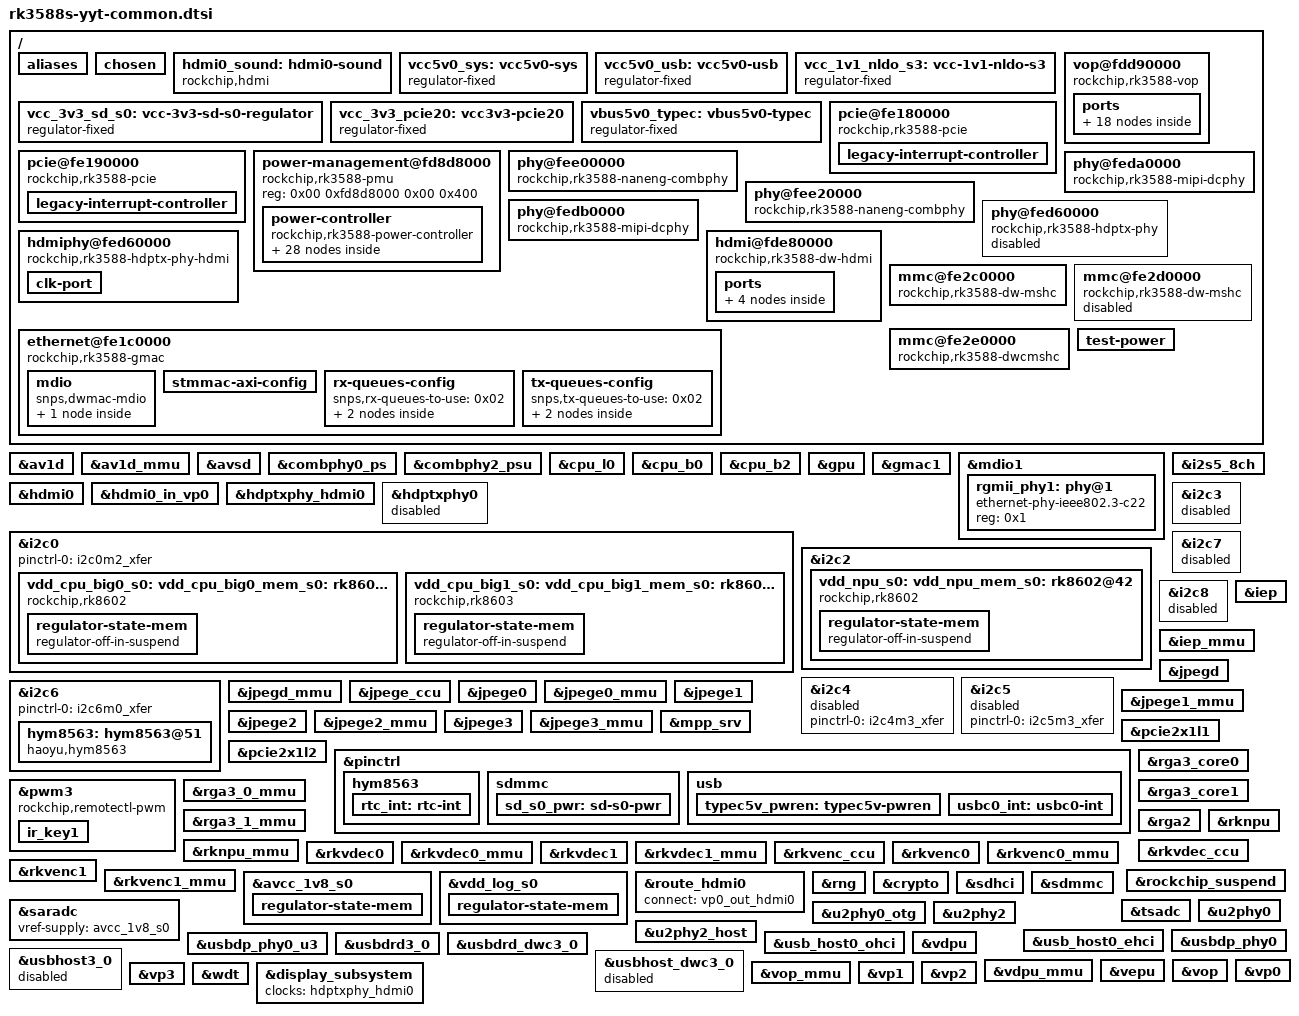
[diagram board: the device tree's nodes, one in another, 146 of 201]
// SPDX-License-Identifier: (GPL-2.0+ OR MIT)
/*
 *
 * Copyright (c) 2021 Rockchip Electronics Co., Ltd.
 */

#include <dt-bindings/gpio/gpio.h>
#include <dt-bindings/pwm/pwm.h>
#include <dt-bindings/pinctrl/rockchip.h>
#include <dt-bindings/input/rk-input.h>
#include <dt-bindings/display/drm_mipi_dsi.h>
#include <dt-bindings/display/rockchip_vop.h>
#include <dt-bindings/sensor-dev.h>
#include <dt-bindings/usb/pd.h>
#include "rk3588s.dtsi"
#include "rk3588-rk806-single.dtsi"
#include "rk3588-linux.dtsi"

/ {
	aliases {
		mmc0 = "/mmc@fe2e0000";
		mmc1 = "/mmc@fe2c0000";
		mmc2 = "/mmc@fe2d0000";
		ethernet1 = "/ethernet@fe1c0000";
	};

	chosen: chosen {
		bootargs = "earlycon=uart8250,mmio32,0xfeb50000 console=ttyFIQ0 coherent_pool=1m irqchip.gicv3_pseudo_nmi=0";
	};

	hdmi0_sound: hdmi0-sound {
		status = "disabled";
		compatible = "rockchip,hdmi";
		rockchip,mclk-fs = <128>;
		rockchip,card-name = "rockchip-hdmi0";
		rockchip,cpu = <&i2s5_8ch>;
		rockchip,codec = <&hdmi0>;
	};

	vcc5v0_sys: vcc5v0-sys {
		compatible = "regulator-fixed";
		regulator-name = "vcc5v0_sys";
		regulator-always-on;
		regulator-boot-on;
		regulator-min-microvolt = <5000000>;
		regulator-max-microvolt = <5000000>;
	};

	vcc5v0_usb: vcc5v0-usb {
		compatible = "regulator-fixed";
		regulator-name = "vcc5v0_usb";
		regulator-always-on;
		regulator-boot-on;
		regulator-min-microvolt = <5000000>;
		regulator-max-microvolt = <5000000>;
		vin-supply = <&vcc5v0_sys>;
	};

	vcc_1v1_nldo_s3: vcc-1v1-nldo-s3 {
		compatible = "regulator-fixed";
		regulator-name = "vcc_1v1_nldo_s3";
		regulator-always-on;
		regulator-boot-on;
		regulator-min-microvolt = <1100000>;
		regulator-max-microvolt = <1100000>;
		vin-supply = <&vcc5v0_sys>;
	};

	vcc_3v3_sd_s0: vcc-3v3-sd-s0-regulator {
		compatible = "regulator-fixed";
		enable-active-high;
		gpio = <&gpio4 RK_PB4 GPIO_ACTIVE_HIGH>;
		pinctrl-names = "default";
		pinctrl-0 = <&sd_s0_pwr>;
		regulator-always-on;
		regulator-boot-on;
		regulator-max-microvolt = <3000000>;
		regulator-min-microvolt = <3000000>;
		regulator-name = "vcc_3v3_sd_s0";
		vin-supply = <&vcc_3v3_s3>;
	};

	vcc_3v3_pcie20: vcc3v3-pcie20 {
		compatible = "regulator-fixed";
		regulator-name = "vcc_3v3_pcie20";
		regulator-always-on;
		regulator-boot-on;
		regulator-min-microvolt = <3300000>;
		regulator-max-microvolt = <3300000>;
		vin-supply = <&vcc_3v3_s3>;
	};

	vbus5v0_typec: vbus5v0-typec {
		compatible = "regulator-fixed";
		enable-active-high;
		gpio = <&gpio1 RK_PD2 GPIO_ACTIVE_HIGH>;
		pinctrl-names = "default";
		pinctrl-0 = <&typec5v_pwren>;
		regulator-name = "vbus5v0_typec";
		regulator-min-microvolt = <5000000>;
		regulator-max-microvolt = <5000000>;
		vin-supply = <&vcc5v0_usb>;
	};

	pcie@fe180000 {
		compatible = "rockchip,rk3588-pcie\0snps,dw-pcie";
		#address-cells = <0x03>;
		#size-cells = <0x02>;
		bus-range = <0x30 0x3f>;
		clocks = <0x02 0x151 0x02 0x156 0x02 0x14c 0x02 0x15c 0x02 0x161 0x02 0x2c5>;
		clock-names = "aclk_mst\0aclk_slv\0aclk_dbi\0pclk\0aux\0pipe";
		device_type = "pci";
		interrupts = <0x00 0xf8 0x04 0x00 0xf7 0x04 0x00 0xf6 0x04 0x00 0xf5 0x04 0x00 0xf4 0x04>;
		interrupt-names = "sys\0pmc\0msg\0legacy\0err";
		#interrupt-cells = <0x01>;
		interrupt-map-mask = <0x00 0x00 0x00 0x07>;
		interrupt-map = <0x00 0x00 0x00 0x01 0xf1 0x00 0x00 0x00 0x00 0x02 0xf1 0x01 0x00 0x00 0x00 0x03 0xf1 0x02 0x00 0x00 0x00 0x04 0xf1 0x03>;
		linux,pci-domain = <0x03>;
		num-ib-windows = <0x08>;
		num-ob-windows = <0x08>;
		num-viewport = <0x04>;
		max-link-speed = <0x02>;
		msi-map = <0x3000 0xf2 0x3000 0x1000>;
		num-lanes = <0x01>;
		phys = <0x62 0x02>;
		phy-names = "pcie-phy";
		ranges = <0x800 0x00 0xf3000000 0x00 0xf3000000 0x00 0x100000 0x81000000 0x00 0xf3100000 0x00 0xf3100000 0x00 0x100000 0x82000000 0x00 0xf3200000 0x00 0xf3200000 0x00 0xe00000 0xc3000000 0x09 0xc0000000 0x09 0xc0000000 0x00 0x40000000>;
		reg = <0x00 0xfe180000 0x00 0x10000 0x0a 0x40c00000 0x00 0x400000>;
		reg-names = "pcie-apb\0pcie-dbi";
		resets = <0x02 0x210 0x02 0x21f>;
		reset-names = "pcie\0periph";
		rockchip,pipe-grf = <0x68>;
		status = "okay";
		reset-gpios = <0xdb 0x08 0x00>;
		pedet-gpios = <0xdb 0x06 0x00>;
		vpcie3v3-supply = <0xf3>;
		rockchip,skip-scan-in-resume;

		legacy-interrupt-controller {
			interrupt-controller;
			#address-cells = <0x00>;
			#interrupt-cells = <0x01>;
			interrupt-parent = <0x01>;
			interrupts = <0x00 0xf5 0x01>;
			phandle = <0xf1>;
		};
	};

	pcie@fe190000 {
		compatible = "rockchip,rk3588-pcie\0snps,dw-pcie";
		#address-cells = <0x03>;
		#size-cells = <0x02>;
		bus-range = <0x40 0x4f>;
		clocks = <0x02 0x152 0x02 0x157 0x02 0x14d 0x02 0x15d 0x02 0x162 0x02 0x182>;
		clock-names = "aclk_mst\0aclk_slv\0aclk_dbi\0pclk\0aux\0pipe";
		device_type = "pci";
		interrupts = <0x00 0xfd 0x04 0x00 0xfc 0x04 0x00 0xfb 0x04 0x00 0xfa 0x04 0x00 0xf9 0x04>;
		interrupt-names = "sys\0pmc\0msg\0legacy\0err";
		#interrupt-cells = <0x01>;
		interrupt-map-mask = <0x00 0x00 0x00 0x07>;
		interrupt-map = <0x00 0x00 0x00 0x01 0xf4 0x00 0x00 0x00 0x00 0x02 0xf4 0x01 0x00 0x00 0x00 0x03 0xf4 0x02 0x00 0x00 0x00 0x04 0xf4 0x03>;
		linux,pci-domain = <0x04>;
		num-ib-windows = <0x08>;
		num-ob-windows = <0x08>;
		num-viewport = <0x04>;
		max-link-speed = <0x02>;
		msi-map = <0x4000 0xf2 0x4000 0x1000>;
		num-lanes = <0x01>;
		phys = <0xf5 0x02>;
		phy-names = "pcie-phy";
		ranges = <0x800 0x00 0xf4000000 0x00 0xf4000000 0x00 0x100000 0x81000000 0x00 0xf4100000 0x00 0xf4100000 0x00 0x100000 0x82000000 0x00 0xf4200000 0x00 0xf4200000 0x00 0xe00000 0xc3000000 0x0a 0x00 0x0a 0x00 0x00 0x40000000>;
		reg = <0x00 0xfe190000 0x00 0x10000 0x0a 0x41000000 0x00 0x400000>;
		reg-names = "pcie-apb\0pcie-dbi";
		resets = <0x02 0x211 0x02 0x220>;
		reset-names = "pcie\0periph";
		rockchip,pipe-grf = <0x68>;
		status = "okay";
		reset-gpios = <0xea 0x07 0x00>;
		vpcie3v3-supply = <0xf3>;
		rockchip,skip-scan-in-resume;

		legacy-interrupt-controller {
			interrupt-controller;
			#address-cells = <0x00>;
			#interrupt-cells = <0x01>;
			interrupt-parent = <0x01>;
			interrupts = <0x00 0xfa 0x01>;
			phandle = <0xf4>;
		};
	};

	vop@fdd90000 {
		compatible = "rockchip,rk3588-vop";
		reg = <0x00 0xfdd90000 0x00 0x4200 0x00 0xfdd95000 0x00 0x1000>;
		reg-names = "regs\0gamma_lut";
		interrupts = <0x00 0x9c 0x04>;
		clocks = <0x02 0x270 0x02 0x26f 0x02 0x274 0x02 0x275 0x02 0x276 0x02 0x277 0x02 0x26e 0x02 0x271 0x02 0x272 0x02 0x273>;
		clock-names = "aclk_vop\0hclk_vop\0dclk_vp0\0dclk_vp1\0dclk_vp2\0dclk_vp3\0pclk_vop\0dclk_src_vp0\0dclk_src_vp1\0dclk_src_vp2";
		assigned-clocks = <0x02 0x270>;
		assigned-clock-rates = <0x2faf0800>;
		resets = <0x02 0x349 0x02 0x348 0x02 0x34d 0x02 0x350 0x02 0x351 0x02 0x352>;
		reset-names = "axi\0ahb\0dclk_vp0\0dclk_vp1\0dclk_vp2\0dclk_vp3";
		iommus = <0xc3>;
		power-domains = <0x54 0x18>;
		rockchip,grf = <0xbe>;
		rockchip,vop-grf = <0xc4>;
		rockchip,vo1-grf = <0xc5>;
		rockchip,pmu = <0xc6>;
		status = "okay";

		ports {
			#address-cells = <0x01>;
			#size-cells = <0x00>;
			phandle = <0x31>;

			port@0 {
				#address-cells = <0x01>;
				#size-cells = <0x00>;
				reg = <0x00>;
				rockchip,plane-mask = <0x05>;
				rockchip,primary-plane = <0x02>;

				endpoint@0 {
					reg = <0x00>;
					remote-endpoint = <0xc7>;
					phandle = <0xe2>;
				};

				endpoint@1 {
					reg = <0x01>;
					remote-endpoint = <0xc8>;
					phandle = <0xee>;
				};

				endpoint@2 {
					reg = <0x02>;
					remote-endpoint = <0xc9>;
					phandle = <0x37>;
				};
			};

			port@1 {
				#address-cells = <0x01>;
				#size-cells = <0x00>;
				reg = <0x01>;
				rockchip,plane-mask = <0x0a>;
				rockchip,primary-plane = <0x03>;

				endpoint@0 {
					reg = <0x00>;
					remote-endpoint = <0xca>;
					phandle = <0x33>;
				};

				endpoint@1 {
					reg = <0x01>;
					remote-endpoint = <0xcb>;
					phandle = <0xef>;
				};

				endpoint@2 {
					reg = <0x02>;
					remote-endpoint = <0xcc>;
					phandle = <0xeb>;
				};
			};

			port@2 {
				#address-cells = <0x01>;
				#size-cells = <0x00>;
				reg = <0x02>;
				assigned-clocks = <0x02 0x273>;
				assigned-clock-parents = <0x02 0x04>;
				rockchip,plane-mask = <0x140>;
				rockchip,primary-plane = <0x08>;

				endpoint@0 {
					reg = <0x00>;
					remote-endpoint = <0xcd>;
					phandle = <0xe3>;
				};

				endpoint@1 {
					reg = <0x01>;
					remote-endpoint = <0xce>;
					phandle = <0x36>;
				};

				endpoint@2 {
					reg = <0x02>;
					remote-endpoint = <0xcf>;
					phandle = <0xec>;
				};

				endpoint@3 {
					reg = <0x03>;
					remote-endpoint = <0xd0>;
					phandle = <0x34>;
				};

				endpoint@4 {
					reg = <0x04>;
					remote-endpoint = <0xd1>;
					phandle = <0xdf>;
				};
			};

			port@3 {
				#address-cells = <0x01>;
				#size-cells = <0x00>;
				reg = <0x03>;
				rockchip,plane-mask = <0x280>;
				rockchip,primary-plane = <0x09>;

				endpoint@0 {
					reg = <0x00>;
					remote-endpoint = <0xd2>;
					phandle = <0xd7>;
				};

				endpoint@1 {
					reg = <0x01>;
					remote-endpoint = <0xd3>;
					phandle = <0x35>;
				};

				endpoint@2 {
					reg = <0x02>;
					remote-endpoint = <0xd4>;
					phandle = <0x38>;
				};
			};
		};
	};

	power-management@fd8d8000 {
		compatible = "rockchip,rk3588-pmu\0syscon\0simple-mfd";
		reg = <0x00 0xfd8d8000 0x00 0x400>;
		phandle = <0xc6>;

		power-controller {
			compatible = "rockchip,rk3588-power-controller";
			#power-domain-cells = <0x01>;
			#address-cells = <0x01>;
			#size-cells = <0x00>;
			status = "okay";
			phandle = <0x54>;

			power-domain@8 {
				reg = <0x08>;
				#address-cells = <0x01>;
				#size-cells = <0x00>;

				power-domain@9 {
					reg = <0x09>;
					#address-cells = <0x01>;
					#size-cells = <0x00>;
					clocks = <0x02 0x12f 0x02 0x131 0x02 0x130 0x02 0x126>;
					pm_qos = <0x71 0x72 0x73>;

					power-domain@10 {
						reg = <0x0a>;
						clocks = <0x02 0x12f 0x02 0x131 0x02 0x130>;
						pm_qos = <0x74>;
					};

					power-domain@11 {
						reg = <0x0b>;
						clocks = <0x02 0x12f 0x02 0x131 0x02 0x130>;
						pm_qos = <0x75>;
					};
				};
			};

			power-domain@12 {
				reg = <0x0c>;
				clocks = <0x02 0x114 0x02 0x115 0x02 0x116>;
				pm_qos = <0x76 0x77 0x78 0x79>;
			};

			power-domain@13 {
				reg = <0x0d>;
				#address-cells = <0x01>;
				#size-cells = <0x00>;

				power-domain@14 {
					reg = <0x0e>;
					clocks = <0x02 0x18f 0x02 0x1be 0x02 0x1bc 0x02 0x190 0x02 0x18e>;
					pm_qos = <0x7a>;
				};

				power-domain@15 {
					reg = <0x0f>;
					clocks = <0x02 0x194 0x02 0x1be 0x02 0x1bc 0x02 0x195>;
					pm_qos = <0x7b>;
				};

				power-domain@16 {
					reg = <0x10>;
					#address-cells = <0x01>;
					#size-cells = <0x00>;
					clocks = <0x02 0x1c4 0x02 0x1c5>;
					pm_qos = <0x7c 0x7d 0x7e>;

					power-domain@17 {
						reg = <0x11>;
						clocks = <0x02 0x1c9 0x02 0x1c4 0x02 0x1c5 0x02 0x1ca>;
						pm_qos = <0x7f 0x80 0x81>;
					};
				};
			};

			power-domain@21 {
				reg = <0x15>;
				#address-cells = <0x01>;
				#size-cells = <0x00>;
				clocks = <0x02 0x1be 0x02 0x1bd 0x02 0x1bc 0x02 0x1bf 0x02 0x1aa 0x02 0x1a9 0x02 0x1ac 0x02 0x1ad 0x02 0x1ae 0x02 0x1af 0x02 0x1b0 0x02 0x1b1 0x02 0x1b2 0x02 0x1b3 0x02 0x1b4 0x02 0x1b5 0x02 0x1b7 0x02 0x1b6>;
				pm_qos = <0x82 0x83 0x84 0x85 0x86 0x87 0x88 0x89>;

				power-domain@23 {
					reg = <0x17>;
					clocks = <0x02 0x4b 0x02 0x49 0x02 0x1be>;
					pm_qos = <0x8a>;
				};

				power-domain@14 {
					reg = <0x0e>;
					clocks = <0x02 0x18f 0x02 0x1be 0x02 0x1bc 0x02 0x190>;
					pm_qos = <0x7a>;
				};

				power-domain@15 {
					reg = <0x0f>;
					clocks = <0x02 0x194 0x02 0x1be 0x02 0x1bc>;
					pm_qos = <0x7b>;
				};

				power-domain@22 {
					reg = <0x16>;
					clocks = <0x02 0x1ba 0x02 0x1b9>;
					pm_qos = <0x8b>;
				};
			};

			power-domain@24 {
				reg = <0x18>;
				#address-cells = <0x01>;
				#size-cells = <0x00>;
				clocks = <0x02 0x26e 0x02 0x26d 0x02 0x270>;
				pm_qos = <0x8c 0x8d>;

				power-domain@25 {
					reg = <0x19>;
					clocks = <0x02 0x1f6 0x02 0x1f7 0x02 0x1f5 0x02 0x1f3 0x02 0x1ee 0x02 0x1ed 0x02 0x26d>;
					pm_qos = <0x8e>;
				};
			};

			power-domain@26 {
				reg = <0x1a>;
				clocks = <0x02 0x22e 0x02 0x22f 0x02 0x22d 0x02 0x218 0x02 0x217 0x02 0x22b 0x02 0x264>;
				pm_qos = <0x8f 0x90>;
			};

			power-domain@27 {
				reg = <0x1b>;
				#address-cells = <0x01>;
				#size-cells = <0x00>;
				clocks = <0x02 0x1e1 0x02 0x1e2 0x02 0x1df 0x02 0x1de 0x02 0x1e5 0x02 0x1e4>;
				pm_qos = <0x91 0x92 0x93 0x94>;

				power-domain@28 {
					reg = <0x1c>;
					clocks = <0x02 0x121 0x02 0x120 0x02 0x1e1 0x02 0x1e2>;
					pm_qos = <0x95 0x96>;
				};

				power-domain@29 {
					reg = <0x1d>;
					clocks = <0x02 0x1d6 0x02 0x1d5 0x02 0x1d9 0x02 0x1d8 0x02 0x1e2>;
					pm_qos = <0x97 0x98>;
				};
			};

			power-domain@30 {
				reg = <0x1e>;
				clocks = <0x02 0x189 0x02 0x18a>;
				pm_qos = <0x99>;
			};

			power-domain@31 {
				reg = <0x1f>;
				clocks = <0x02 0x166 0x02 0x19b 0x02 0x19c 0x02 0x19d 0x02 0x19e 0x02 0x19f 0x02 0x1a0>;
				pm_qos = <0x9a 0x9b 0x9c 0x9d>;
			};

			power-domain@33 {
				reg = <0x21>;
				clocks = <0x02 0x166 0x02 0x169 0x02 0x16a>;
			};

			power-domain@34 {
				reg = <0x22>;
				clocks = <0x02 0x166 0x02 0x169 0x02 0x16a>;
			};

			power-domain@37 {
				reg = <0x25>;
				clocks = <0x02 0x199 0x02 0x140>;
				pm_qos = <0x9e>;
			};

			power-domain@38 {
				reg = <0x26>;
				clocks = <0x02 0x3c 0x02 0x3d>;
			};

			power-domain@40 {
				reg = <0x28>;
				pm_qos = <0x9f>;
			};
		};
	};

	phy@fee00000 {
		compatible = "rockchip,rk3588-naneng-combphy";
		reg = <0x00 0xfee00000 0x00 0x100>;
		#phy-cells = <0x01>;
		clocks = <0x02 0x2bd 0x02 0x185 0x02 0x166>;
		clock-names = "refclk\0apbclk\0phpclk";
		assigned-clocks = <0x02 0x2bd>;
		assigned-clock-rates = <0x5f5e100>;
		resets = <0x02 0x20005 0x02 0x4d6>;
		reset-names = "combphy-apb\0combphy";
		rockchip,pipe-grf = <0x68>;
		rockchip,pipe-phy-grf = <0x17d>;
		status = "okay";
		phandle = <0xf5>;
	};

	phy@fee20000 {
		compatible = "rockchip,rk3588-naneng-combphy";
		reg = <0x00 0xfee20000 0x00 0x100>;
		#phy-cells = <0x01>;
		clocks = <0x02 0x2bf 0x02 0x187 0x02 0x166>;
		clock-names = "refclk\0apbclk\0phpclk";
		assigned-clocks = <0x02 0x2bf>;
		assigned-clock-rates = <0x5f5e100>;
		resets = <0x02 0x20007 0x02 0x4d8>;
		reset-names = "combphy-apb\0combphy";
		rockchip,pipe-grf = <0x68>;
		rockchip,pipe-phy-grf = <0x17e>;
		rockchip,pcie1ln-sel-bits = <0x100 0x01 0x01 0x00>;
		status = "okay";
		phandle = <0x62>;
	};

		phy@feda0000 {
		compatible = "rockchip,rk3588-mipi-dcphy";
		reg = <0x00 0xfeda0000 0x00 0x10000>;
		rockchip,grf = <0x17a>;
		clocks = <0x02 0x108 0x02 0x2b6>;
		clock-names = "pclk\0ref";
		resets = <0x02 0xc0043 0x02 0x3e 0x02 0x3f 0x02 0xc0044>;
		reset-names = "m_phy\0apb\0grf\0s_phy";
		#phy-cells = <0x00>;
		status = "okay";
		phandle = <0x2a>;
	};

	phy@fedb0000 {
		compatible = "rockchip,rk3588-mipi-dcphy";
		reg = <0x00 0xfedb0000 0x00 0x10000>;
		rockchip,grf = <0x17b>;
		clocks = <0x02 0x109 0x02 0x2b6>;
		clock-names = "pclk\0ref";
		resets = <0x02 0xc0045 0x02 0x43 0x02 0x44 0x02 0xc0046>;
		reset-names = "m_phy\0apb\0grf\0s_phy";
		#phy-cells = <0x00>;
		status = "okay";
		phandle = <0x2d>;
	};

	phy@fed60000 {
		compatible = "rockchip,rk3588-hdptx-phy";
		reg = <0x00 0xfed60000 0x00 0x2000>;
		clocks = <0x02 0x2b5 0x02 0x267>;
		clock-names = "ref\0apb";
		resets = <0x02 0x485 0x02 0xc003b 0x02 0xc003c 0x02 0xc003d>;
		reset-names = "apb\0init\0cmn\0lane";
		rockchip,grf = <0x174>;
		#phy-cells = <0x00>;
		status = "disabled";
		phandle = <0xed>;
	};

	hdmiphy@fed60000 {
		compatible = "rockchip,rk3588-hdptx-phy-hdmi";
		reg = <0x00 0xfed60000 0x00 0x2000>;
		clocks = <0x02 0x2b5 0x02 0x267>;
		clock-names = "ref\0apb";
		resets = <0x02 0x48e 0x02 0x485 0x02 0xc003b 0x02 0xc003c 0x02 0xc003d 0x02 0x48c 0x02 0x48d>;
		reset-names = "phy\0apb\0init\0cmn\0lane\0ropll\0lcpll";
		rockchip,grf = <0x174>;
		#phy-cells = <0x00>;
		status = "okay";
		phandle = <0xe9>;

		clk-port {
			#clock-cells = <0x00>;
			status = "okay";
			phandle = <0xe4>;
		};
	};

	hdmi@fde80000 {
		compatible = "rockchip,rk3588-dw-hdmi";
		reg = <0x00 0xfde80000 0x00 0x20000>;
		interrupts = <0x00 0xa9 0x04 0x00 0xaa 0x04 0x00 0xab 0x04 0x00 0xac 0x04 0x00 0x168 0x04>;
		clocks = <0x02 0x221 0x02 0x265 0x02 0x222 0x02 0x223 0x02 0x246 0x02 0x274 0x02 0x275 0x02 0x276 0x02 0x277 0x05 0xe4>;
		clock-names = "pclk\0hpd\0earc\0hdmitx_ref\0aud\0dclk_vp0\0dclk_vp1\0dclk_vp2\0dclk_vp3\0hclk_vo1\0link_clk";
		resets = <0x02 0x3d0 0x02 0x49c>;
		reset-names = "ref\0hdp";
		power-domains = <0x54 0x1a>;
		pinctrl-names = "default";
		pinctrl-0 = <0xe5 0xe6 0xe7 0xe8>;
		reg-io-width = <0x04>;
		rockchip,grf = <0xbe>;
		rockchip,vo1_grf = <0xc5>;
		phys = <0xe9>;
		phy-names = "hdmi";
		#sound-dai-cells = <0x00>;
		status = "okay";
		enable-gpios = <0xea 0x0e 0x00>;
		phandle = <0x191>;

		ports {
			#address-cells = <0x01>;
			#size-cells = <0x00>;

			port@0 {
				reg = <0x00>;
				#address-cells = <0x01>;
				#size-cells = <0x00>;

				endpoint@0 {
					reg = <0x00>;
					remote-endpoint = <0x37>;
					status = "disabled";
					phandle = <0xc9>;
				};

				endpoint@1 {
					reg = <0x01>;
					remote-endpoint = <0xeb>;
					status = "okay";
					phandle = <0xcc>;
				};

				endpoint@2 {
					reg = <0x02>;
					remote-endpoint = <0xec>;
					status = "disabled";
					phandle = <0xcf>;
				};
			};
		};
	};

	ethernet@fe1c0000 {
		compatible = "rockchip,rk3588-gmac\0snps,dwmac-4.20a";
		reg = <0x00 0xfe1c0000 0x00 0x10000>;
		interrupts = <0x00 0xea 0x04 0x00 0xe9 0x04>;
		interrupt-names = "macirq\0eth_wake_irq";
		rockchip,grf = <0xbe>;
		rockchip,php_grf = <0x68>;
		clocks = <0x02 0x144 0x02 0x145 0x02 0x168 0x02 0x16d 0x02 0x143>;
		clock-names = "stmmaceth\0clk_mac_ref\0pclk_mac\0aclk_mac\0ptp_ref";
		resets = <0x02 0x20b>;
		reset-names = "stmmaceth";
		power-domains = <0x54 0x21>;
		snps,mixed-burst;
		snps,tso;
		snps,axi-config = <0xf6>;
		snps,mtl-rx-config = <0xf7>;
		snps,mtl-tx-config = <0xf8>;
		status = "okay";
		phy-mode = "rgmii-rxid";
		clock_in_out = "input";
		snps,reset-gpio = <0xf9 0x0f 0x01>;
		snps,reset-active-high;
		snps,reset-delays-us = <0x00 0x4e20 0x186a0>;
		pinctrl-names = "default";
		pinctrl-0 = <0xfa 0xfb 0xfc 0xfd 0xfe 0xff 0x100>;
		tx_delay = <0x44>;
		rx_delay = <0x18>;
		phy-handle = <0x101>;

		mdio {
			compatible = "snps,dwmac-mdio";
			#address-cells = <0x01>;
			#size-cells = <0x00>;

			phy@0 {
				compatible = "ethernet-phy-ieee802.3-c22";
				reg = <0x00>;
				phandle = <0x101>;
			};
		};

		stmmac-axi-config {
			snps,wr_osr_lmt = <0x04>;
			snps,rd_osr_lmt = <0x08>;
			snps,blen = <0x00 0x00 0x00 0x00 0x10 0x08 0x04>;
			phandle = <0xf6>;
		};

		rx-queues-config {
			snps,rx-queues-to-use = <0x02>;
			phandle = <0xf7>;

			queue0 {
			};

			queue1 {
			};
		};

		tx-queues-config {
			snps,tx-queues-to-use = <0x02>;
			phandle = <0xf8>;

			queue0 {
			};

			queue1 {
			};
		};
	};

	mmc@fe2c0000 {
		compatible = "rockchip,rk3588-dw-mshc\0rockchip,rk3288-dw-mshc";
		reg = <0x00 0xfe2c0000 0x00 0x4000>;
		interrupts = <0x00 0xcb 0x04>;
		clocks = <0x0e 0x17 0x0e 0x09 0x02 0x2c2 0x02 0x2c3>;
		clock-names = "biu\0ciu\0ciu-drive\0ciu-sample";
		fifo-depth = <0x100>;
		max-frequency = <0x8f0d180>;
		pinctrl-names = "default";
		pinctrl-0 = <0x102 0x103 0x104 0x105>;
		power-domains = <0x54 0x28>;
		status = "okay";
		no-sdio;
		no-mmc;
		bus-width = <0x04>;
		cap-mmc-highspeed;
		cap-sd-highspeed;
		disable-wp;
		sd-uhs-sdr104;
		vmmc-supply = <0x106>;
		vqmmc-supply = <0x107>;
	};

	mmc@fe2d0000 {
		compatible = "rockchip,rk3588-dw-mshc\0rockchip,rk3288-dw-mshc";
		reg = <0x00 0xfe2d0000 0x00 0x4000>;
		interrupts = <0x00 0xcc 0x04>;
		clocks = <0x02 0x199 0x02 0x19a 0x02 0x2c0 0x02 0x2c1>;
		clock-names = "biu\0ciu\0ciu-drive\0ciu-sample";
		fifo-depth = <0x100>;
		max-frequency = <0xbebc200>;
		pinctrl-names = "default";
		pinctrl-0 = <0x108>;
		power-domains = <0x54 0x25>;
		status = "disabled";
	};

	mmc@fe2e0000 {
		compatible = "rockchip,rk3588-dwcmshc\0rockchip,dwcmshc-sdhci";
		reg = <0x00 0xfe2e0000 0x00 0x10000>;
		interrupts = <0x00 0xcd 0x04>;
		assigned-clocks = <0x02 0x13b 0x02 0x13c 0x02 0x13a>;
		assigned-clock-rates = <0xbebc200 0x16e3600 0xbebc200>;
		clocks = <0x02 0x13a 0x02 0x138 0x02 0x139 0x02 0x13b 0x02 0x13c>;
		clock-names = "core\0bus\0axi\0block\0timer";
		resets = <0x02 0x1f6 0x02 0x1f4 0x02 0x1f5 0x02 0x1f7 0x02 0x1f8>;
		reset-names = "core\0bus\0axi\0block\0timer";
		max-frequency = <0xbebc200>;
		status = "okay";
		bus-width = <0x08>;
		no-sdio;
		no-sd;
		non-removable;
		mmc-hs400-1_8v;
		mmc-hs400-enhanced-strobe;
	};


	test-power {
		status = "okay";
	};
};

&av1d {
	status = "okay";
};

&av1d_mmu {
	status = "okay";
};

&avsd {
	status = "okay";
};

&combphy0_ps {
	status = "okay";
};

&combphy2_psu {
	status = "okay";
};

&cpu_l0 {
	cpu-supply = <&vdd_cpu_lit_s0>;
	mem-supply = <&vdd_cpu_lit_mem_s0>;
};

&cpu_b0 {
	cpu-supply = <&vdd_cpu_big0_s0>;
	mem-supply = <&vdd_cpu_big0_mem_s0>;
};

&cpu_b2 {
	cpu-supply = <&vdd_cpu_big1_s0>;
	mem-supply = <&vdd_cpu_big1_mem_s0>;
};

&gpu {
	mali-supply = <&vdd_gpu_s0>;
	mem-supply = <&vdd_gpu_mem_s0>;
	upthreshold = <60>;
	downdifferential = <30>;
	status = "okay";
};

&gmac1 {
	/* Use rgmii-rxid mode to disable rx delay inside Soc */
	phy-mode = "rgmii-rxid";
	clock_in_out = "output";

	snps,no-vlhash;
	snps,reset-gpio = <&gpio3 RK_PB7 GPIO_ACTIVE_LOW>;
	snps,reset-active-low;
	/* Reset time is 20ms, 100ms for rtl8211f */
	snps,reset-delays-us = <0 20000 100000>;

	pinctrl-names = "default";
	pinctrl-0 = <&gmac1_miim
		     &gmac1_tx_bus2
		     &gmac1_rx_bus2
		     &gmac1_rgmii_clk
		     &gmac1_rgmii_bus>;

	tx_delay = <0x42>;
	/* rx_delay = <0x4f>; */

	phy-handle = <&rgmii_phy1>;
	status = "okay";
};

&mdio1 {
	rgmii_phy1: phy@1 {
		compatible = "ethernet-phy-ieee802.3-c22";
		reg = <0x1>;
	};
};

&i2s5_8ch {
	status = "okay";
};

&hdmi0 {
	enable-gpios = <&gpio4 RK_PB6 GPIO_ACTIVE_HIGH>;
	status = "okay";
	cec-enable = "true";
};

&hdmi0_in_vp0 {
	status = "okay";
};

&hdmi0_sound {
	status = "okay";
};

&hdptxphy_hdmi0 {
	status = "okay";
};

&hdptxphy0 {
	/* Single Vdiff Training Table for power reduction (optional) */
	training-table = /bits/ 8 <
		/* voltage swing 0, pre-emphasis 0->3 */
		0x0d 0x00 0x00 0x00 0x00 0x00
		0x0d 0x00 0x00 0x00 0x00 0x00
		0x0d 0x00 0x00 0x00 0x00 0x00
		0x0d 0x00 0x00 0x00 0x00 0x00
		/* voltage swing 1, pre-emphasis 0->2 */
		0x0d 0x00 0x00 0x00 0x00 0x00
		0x0d 0x00 0x00 0x00 0x00 0x00
		0x0d 0x00 0x00 0x00 0x00 0x00
		/* voltage swing 2, pre-emphasis 0->1 */
		0x0d 0x00 0x00 0x00 0x00 0x00
		0x0d 0x00 0x00 0x00 0x00 0x00
		/* voltage swing 3, pre-emphasis 0 */
		0x0d 0x00 0x00 0x00 0x00 0x00
	>;
	status = "disabled";
};

&i2c0 {
	status = "okay";
	pinctrl-names = "default";
	pinctrl-0 = <&i2c0m2_xfer>;

	vdd_cpu_big0_s0: vdd_cpu_big0_mem_s0: rk8602@42 {
		compatible = "rockchip,rk8602";
		reg = <0x42>;
		vin-supply = <&vcc5v0_sys>;
		regulator-compatible = "rk860x-reg";
		regulator-name = "vdd_cpu_big0_s0";
		regulator-min-microvolt = <550000>;
		regulator-max-microvolt = <1050000>;
		regulator-ramp-delay = <2300>;
		rockchip,suspend-voltage-selector = <1>;
		regulator-boot-on;
		regulator-always-on;
		regulator-state-mem {
			regulator-off-in-suspend;
		};
	};

	vdd_cpu_big1_s0: vdd_cpu_big1_mem_s0: rk8603@43 {
		compatible = "rockchip,rk8603";
		reg = <0x43>;
		vin-supply = <&vcc5v0_sys>;
		regulator-compatible = "rk860x-reg";
		regulator-name = "vdd_cpu_big1_s0";
		regulator-min-microvolt = <550000>;
		regulator-max-microvolt = <1050000>;
		regulator-ramp-delay = <2300>;
		rockchip,suspend-voltage-selector = <1>;
		regulator-boot-on;
		regulator-always-on;
		regulator-state-mem {
			regulator-off-in-suspend;
		};
	};
};

&i2c2 {
	status = "okay";

	vdd_npu_s0: vdd_npu_mem_s0: rk8602@42 {
		compatible = "rockchip,rk8602";
		reg = <0x42>;
		vin-supply = <&vcc5v0_sys>;
		regulator-compatible = "rk860x-reg";
		regulator-name = "vdd_npu_s0";
		regulator-min-microvolt = <550000>;
		regulator-max-microvolt = <950000>;
		regulator-ramp-delay = <2300>;
		rockchip,suspend-voltage-selector = <1>;
		regulator-boot-on;
		regulator-always-on;
		regulator-state-mem {
			regulator-off-in-suspend;
		};
	};
};

&i2c3 {
	status = "disabled";
};

&i2c4 {
	status = "disabled";
	pinctrl-names = "default";
	pinctrl-0 = <&i2c4m3_xfer>;
};

&i2c5 {
	status = "disabled";
	pinctrl-names = "default";
	pinctrl-0 = <&i2c5m3_xfer>;
};

&i2c6 {
	status = "okay";
	pinctrl-names = "default";
	pinctrl-0 = <&i2c6m0_xfer>;

	hym8563: hym8563@51 {
		compatible = "haoyu,hym8563";
		reg = <0x51>;
		#clock-cells = <0>;
		clock-frequency = <32768>;
		clock-output-names = "hym8563";
		pinctrl-names = "default";
		pinctrl-0 = <&rtc_int>;

		interrupt-parent = <&gpio0>;
		interrupts = <RK_PB0 IRQ_TYPE_LEVEL_LOW>;
		wakeup-source;
	};
};

&i2c7 {
	status = "disabled";
};

&i2c8 {
	status = "disabled";
};

&iep {
	status = "okay";
};

&iep_mmu {
	status = "okay";
};

&jpegd {
	status = "okay";
};

&jpegd_mmu {
	status = "okay";
};

&jpege_ccu {
	status = "okay";
};

&jpege0 {
	status = "okay";
};

&jpege0_mmu {
	status = "okay";
};

&jpege1 {
	status = "okay";
};

&jpege1_mmu {
	status = "okay";
};

&jpege2 {
	status = "okay";
};

&jpege2_mmu {
	status = "okay";
};

&jpege3 {
	status = "okay";
};

&jpege3_mmu {
	status = "okay";
};

&mpp_srv {
	status = "okay";
};

&pcie2x1l1 {
	reset-gpios = <&gpio1 RK_PA7 GPIO_ACTIVE_HIGH>;
	rockchip,init-delay-ms = <100>;
	vpcie3v3-supply = <&vcc_3v3_pcie20>;
	status = "okay";
};

&pcie2x1l2 {
	reset-gpios = <&gpio3 RK_PD1 GPIO_ACTIVE_HIGH>;
	vpcie3v3-supply = <&vcc_3v3_pcie20>;
	status = "okay";
};

&pinctrl {
	hym8563 {
		rtc_int: rtc-int {
			rockchip,pins = <0 RK_PB0 RK_FUNC_GPIO &pcfg_pull_up>;
		};
	};

	sdmmc {
		sd_s0_pwr: sd-s0-pwr {
			rockchip,pins = <4 RK_PB4 RK_FUNC_GPIO &pcfg_pull_up>;
		};
	};

	usb {
		typec5v_pwren: typec5v-pwren {
			rockchip,pins = <1 RK_PD2 RK_FUNC_GPIO &pcfg_pull_none>;
		};

		/omit-if-no-ref/
		usbc0_int: usbc0-int {
			rockchip,pins = <0 RK_PD3 RK_FUNC_GPIO &pcfg_pull_up>;
		};
	};
};

&pwm3 {
	compatible = "rockchip,remotectl-pwm";
	pinctrl-names = "default";
	pinctrl-0 = <&pwm3m0_pins>;
	remote_pwm_id = <3>;
	handle_cpu_id = <1>;
	remote_support_psci = <0>;
	status = "okay";

	ir_key1 {
		rockchip,usercode = <0xc43b>;
		/* /system/usr/keylayout/Generic.kl */
		rockchip,key_table =
			<0xff	KEY_POWER>,
			<0xef	KEY_LEFT>,
			<0xed	KEY_RIGHT>,
			<0xf2	KEY_UP>,
			<0xea	KEY_DOWN>,
			<0xee	KEY_ENTER>,
			<0xe9	KEY_MUTE>,
			<0xf1	KEY_VOLUMEDOWN>,
			<0xf3	KEY_VOLUMEUP>,
			<0xae	KEY_MENU>,
			<0xeb	KEY_LEFTMETA>,
			<0xaf	KEY_BACK>,
			<0xf7	KEY_MODE>,
			<0xe5	KEY_SYSRQ>,
			<0xf5	KEY_ESC>;
	};
};

&rga3_core0 {
	status = "okay";
};

&rga3_0_mmu {
	status = "okay";
};

&rga3_core1 {
	status = "okay";
};

&rga3_1_mmu {
	status = "okay";
};

&rga2 {
	status = "okay";
};

&rknpu {
	rknpu-supply = <&vdd_npu_s0>;
	mem-supply = <&vdd_npu_mem_s0>;
	status = "okay";
};

&rknpu_mmu {
	status = "okay";
};

&rkvdec_ccu {
	status = "okay";
};

&rkvdec0 {
	status = "okay";
};

&rkvdec0_mmu {
	status = "okay";
};

&rkvdec1 {
	status = "okay";
};

&rkvdec1_mmu {
	status = "okay";
};

&rkvenc_ccu {
	status = "okay";
};

&rkvenc0 {
	venc-supply = <&vdd_vdenc_s0>;
	mem-supply = <&vdd_vdenc_mem_s0>;
	status = "okay";
};

&rkvenc0_mmu {
	status = "okay";
};

&rkvenc1 {
	venc-supply = <&vdd_vdenc_s0>;
	mem-supply = <&vdd_vdenc_mem_s0>;
	status = "okay";
};

&rkvenc1_mmu {
	status = "okay";
};

&avcc_1v8_s0 {
	regulator-state-mem {
		regulator-on-in-suspend;
		regulator-suspend-microvolt = <1800000>;
	};
};

&vdd_log_s0 {
	regulator-state-mem {
		regulator-on-in-suspend;
		regulator-suspend-microvolt = <750000>;
	};
};

&rockchip_suspend {
	status = "okay";
	rockchip,sleep-debug-en = <1>;
	rockchip,sleep-mode-config = <
		(0
		| RKPM_SLP_ARMOFF_DDRPD
		)
	>;
	rockchip,wakeup-config = <
		(0
		| RKPM_CPU0_WKUP_EN
		| RKPM_GPIO_WKUP_EN
		)
	>;
};

&route_hdmi0 {
	status = "okay";
	connect = <&vp0_out_hdmi0>;
};

&rng {
	status = "okay";
};

&crypto {
	status = "okay";
};

&saradc {
	status = "okay";
	vref-supply = <&avcc_1v8_s0>;
};

&sdhci {
	bus-width = <8>;
	no-sdio;
	no-sd;
	non-removable;
	max-frequency = <200000000>;
	mmc-hs400-1_8v;
	mmc-hs400-enhanced-strobe;
	full-pwr-cycle-in-suspend;
	status = "okay";
};

&sdmmc {
	max-frequency = <200000000>;
	no-sdio;
	no-mmc;
	bus-width = <4>;
	cap-mmc-highspeed;
	cap-sd-highspeed;
	disable-wp;
	sd-uhs-sdr104;
	vmmc-supply = <&vcc_3v3_sd_s0>;
	vqmmc-supply = <&vccio_sd_s0>;
	pinctrl-names = "default";
	pinctrl-0 = <&sdmmc_bus4 &sdmmc_clk &sdmmc_cmd &sdmmc_det>;
	status = "okay";
};

&tsadc {
	status = "okay";
};

&u2phy0 {
	status = "okay";
};

&u2phy0_otg {
	status = "okay";
};

&u2phy2 {
	status = "okay";
};

&u2phy2_host {
	status = "okay";
};

&usb_host0_ehci {
	status = "okay";
};

&usb_host0_ohci {
	status = "okay";
};

&usbdp_phy0 {
	status = "okay";
};

&usbdp_phy0_u3 {
	status = "okay";
};

&usbdrd3_0 {
	status = "okay";
};

&usbdrd_dwc3_0 {
	dr_mode = "host";
	extcon = <&u2phy0>;
	status = "okay";
};

&usbhost3_0 {
	status = "disabled";
};

&usbhost_dwc3_0 {
	status = "disabled";
};

&vdpu {
	status = "okay";
};

&vdpu_mmu {
	status = "okay";
};

&vepu {
        status = "okay";
};

&vop {
	assigned-clocks = <&cru ACLK_VOP>;
	assigned-clock-rates = <800000000>;
	status = "okay";
	disable-win-move;
};

&vop_mmu {
	status = "okay";
};

/* vp0 & vp1 splice for 8K output */
&vp0 {
	cursor-win-id=<ROCKCHIP_VOP2_ESMART0>;
	rockchip,plane-mask = <(1 << ROCKCHIP_VOP2_CLUSTER0 | 1 << ROCKCHIP_VOP2_ESMART0)>;
	rockchip,primary-plane = <ROCKCHIP_VOP2_CLUSTER0>;
};

&vp1 {
	cursor-win-id=<ROCKCHIP_VOP2_ESMART1>;
	rockchip,plane-mask = <(1 << ROCKCHIP_VOP2_CLUSTER1 | 1 << ROCKCHIP_VOP2_ESMART1)>;
	rockchip,primary-plane = <ROCKCHIP_VOP2_CLUSTER1>;
};

&vp2 {
	cursor-win-id=<ROCKCHIP_VOP2_ESMART2>;
	rockchip,plane-mask = <(1 << ROCKCHIP_VOP2_CLUSTER2 | 1 << ROCKCHIP_VOP2_ESMART2)>;
	rockchip,primary-plane = <ROCKCHIP_VOP2_CLUSTER2>;
};

&vp3 {
	cursor-win-id=<ROCKCHIP_VOP2_ESMART3>;
	rockchip,plane-mask = <(1 << ROCKCHIP_VOP2_CLUSTER3 | 1 << ROCKCHIP_VOP2_ESMART3)>;
	rockchip,primary-plane = <ROCKCHIP_VOP2_CLUSTER3>;
};

&wdt {
	status = "okay";
};

&display_subsystem {
	clocks = <&hdptxphy_hdmi0>;
	clock-names = "hdmi0_phy_pll";
};
